# ioat91sam7x256 register map
Registers are 32-bit, access not given, no defined reset value unless marked. A register's access mark holds for its fields unless they carry their own. Addresses are absolute; registers are grouped by the start of their names; [hi:lo] are bit positions; {n}, {i} and the like mark numbered series; 'fields as' and 'values as' point back to an identical list.

## UDP
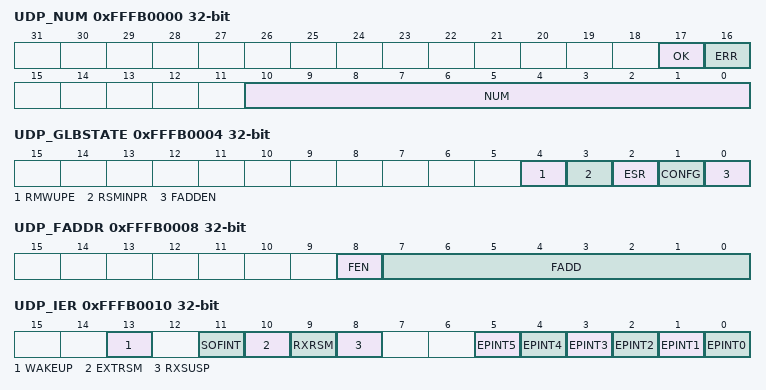
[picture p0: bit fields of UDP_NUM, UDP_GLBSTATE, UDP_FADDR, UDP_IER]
0xFFFB0000 UDP_NUM
  [17] OK, [16] ERR, [10:0] NUM
0xFFFB0004 UDP_GLBSTATE
  [4] RMWUPE, [3] RSMINPR, [2] ESR, [1] CONFG, [0] FADDEN
0xFFFB0008 UDP_FADDR
  [8] FEN, [7:0] FADD
0xFFFB0010 UDP_IER
  [13] WAKEUP, [11] SOFINT, [10] EXTRSM, [9] RXRSM, [8] RXSUSP, [n] EPINT{n} (n=0..5)
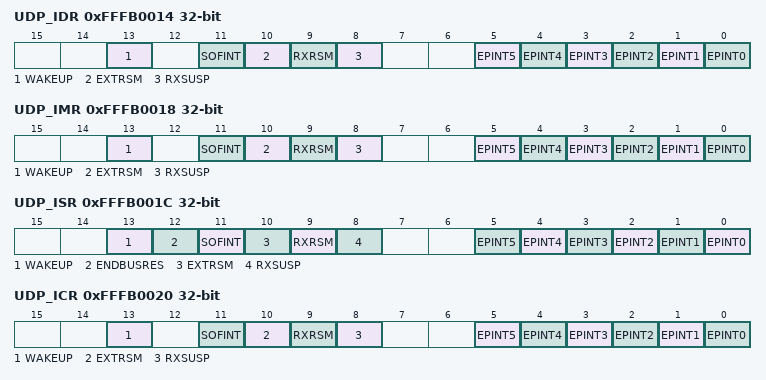
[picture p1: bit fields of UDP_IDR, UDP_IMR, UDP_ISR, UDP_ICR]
0xFFFB0014 UDP_IDR
  fields as UDP_IER
0xFFFB0018 UDP_IMR
  fields as UDP_IER
0xFFFB001C UDP_ISR
  [13] WAKEUP, [12] ENDBUSRES, [11] SOFINT, [10] EXTRSM, [9] RXRSM, [8] RXSUSP, [n] EPINT{n} (n=0..5)
0xFFFB0020 UDP_ICR
  fields as UDP_IER
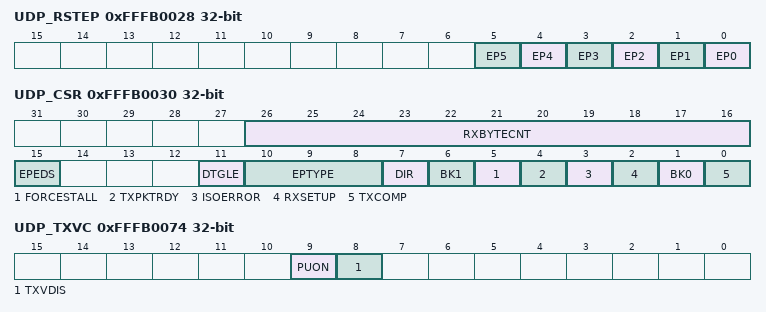
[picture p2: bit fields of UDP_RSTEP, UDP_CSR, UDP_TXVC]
0xFFFB0028 UDP_RSTEP
  [n] EP{n} (n=0..5)
0xFFFB0030 UDP_CSR
  [26:16] RXBYTECNT, [15] EPEDS, [11] DTGLE, [10:8] EPTYPE, [7] DIR, [6] BK1, [5] FORCESTALL, [4] TXPKTRDY, [3] ISOERROR, [2] RXSETUP, [1] BK0, [0] TXCOMP
0xFFFB0050 UDP_FDR
0xFFFB0074 UDP_TXVC
  [9] PUON, [8] TXVDIS

## TC0
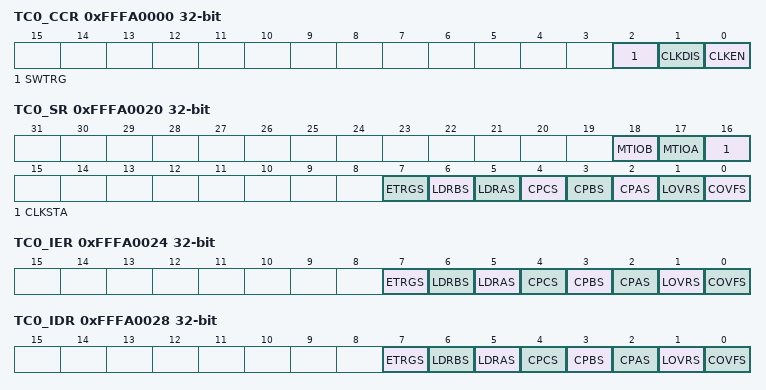
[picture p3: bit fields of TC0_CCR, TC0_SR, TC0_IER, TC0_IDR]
0xFFFA0000 TC0_CCR
  [2] SWTRG, [1] CLKDIS, [0] CLKEN
0xFFFA0004 TC0_CMR
  [31:30] BSWTRG, [29:28] BEEVT, [27:26] BCPC, [25:24] BCPB, [23:22] ASWTRG, [21:20] AEEVT, [19:18] ACPC, [19:18] LDRB, [17:16] ACPA, [17:16] LDRA, [15] WAVE, [14] CPCTRG, [14:13] WAVESEL, [12] ENETRG, [11:10] EEVT, [10] ABETRG, [9:8] ETRGEDG, [9:8] EEVTEDG, [7] CPCDIS, [7] LDBDIS, [6] CPCSTOP, [6] LDBSTOP, [5:4] BURST, [3] CLKI, [2:0] CLKS
0xFFFA0010 TC0_CV
0xFFFA0014 TC0_RA
0xFFFA0018 TC0_RB
0xFFFA001C TC0_RC
0xFFFA0020 TC0_SR
  [18] MTIOB, [17] MTIOA, [16] CLKSTA, [7] ETRGS, [6] LDRBS, [5] LDRAS, [4] CPCS, [3] CPBS, [2] CPAS, [1] LOVRS, [0] COVFS
0xFFFA0024 TC0_IER
  [7] ETRGS, [6] LDRBS, [5] LDRAS, [4] CPCS, [3] CPBS, [2] CPAS, [1] LOVRS, [0] COVFS
0xFFFA0028 TC0_IDR
  fields as TC0_IER
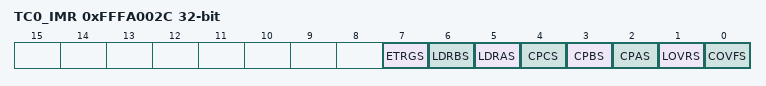
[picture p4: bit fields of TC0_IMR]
0xFFFA002C TC0_IMR
  fields as TC0_IER

## TC1
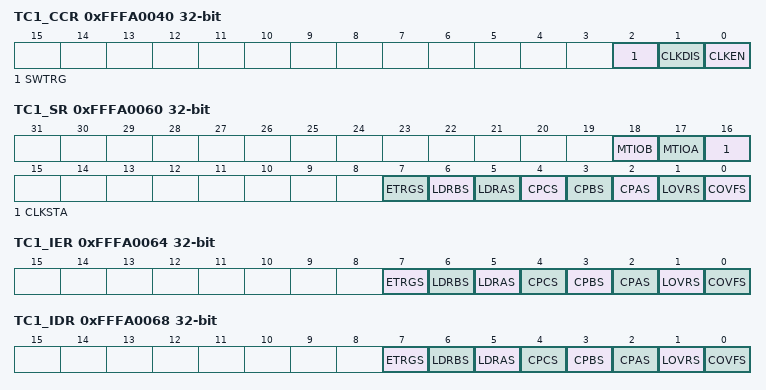
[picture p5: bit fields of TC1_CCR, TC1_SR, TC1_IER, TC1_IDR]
0xFFFA0040 TC1_CCR
  [2] SWTRG, [1] CLKDIS, [0] CLKEN
0xFFFA0044 TC1_CMR
  [31:30] BSWTRG, [29:28] BEEVT, [27:26] BCPC, [25:24] BCPB, [23:22] ASWTRG, [21:20] AEEVT, [19:18] ACPC, [19:18] LDRB, [17:16] ACPA, [17:16] LDRA, [15] WAVE, [14] CPCTRG, [14:13] WAVESEL, [12] ENETRG, [11:10] EEVT, [10] ABETRG, [9:8] ETRGEDG, [9:8] EEVTEDG, [7] CPCDIS, [7] LDBDIS, [6] CPCSTOP, [6] LDBSTOP, [5:4] BURST, [3] CLKI, [2:0] CLKS
0xFFFA0050 TC1_CV
0xFFFA0054 TC1_RA
0xFFFA0058 TC1_RB
0xFFFA005C TC1_RC
0xFFFA0060 TC1_SR
  [18] MTIOB, [17] MTIOA, [16] CLKSTA, [7] ETRGS, [6] LDRBS, [5] LDRAS, [4] CPCS, [3] CPBS, [2] CPAS, [1] LOVRS, [0] COVFS
0xFFFA0064 TC1_IER
  [7] ETRGS, [6] LDRBS, [5] LDRAS, [4] CPCS, [3] CPBS, [2] CPAS, [1] LOVRS, [0] COVFS
0xFFFA0068 TC1_IDR
  fields as TC1_IER
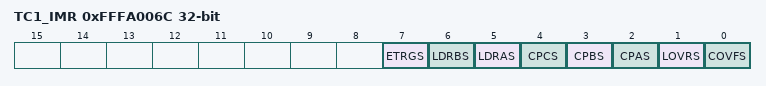
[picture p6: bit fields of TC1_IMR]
0xFFFA006C TC1_IMR
  fields as TC1_IER

## TC2
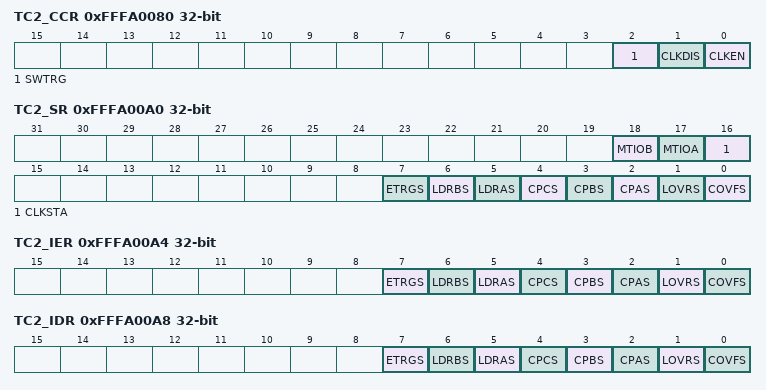
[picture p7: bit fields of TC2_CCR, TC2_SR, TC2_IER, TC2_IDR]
0xFFFA0080 TC2_CCR
  [2] SWTRG, [1] CLKDIS, [0] CLKEN
0xFFFA0084 TC2_CMR
  [31:30] BSWTRG, [29:28] BEEVT, [27:26] BCPC, [25:24] BCPB, [23:22] ASWTRG, [21:20] AEEVT, [19:18] ACPC, [19:18] LDRB, [17:16] ACPA, [17:16] LDRA, [15] WAVE, [14] CPCTRG, [14:13] WAVESEL, [12] ENETRG, [11:10] EEVT, [10] ABETRG, [9:8] ETRGEDG, [9:8] EEVTEDG, [7] CPCDIS, [7] LDBDIS, [6] CPCSTOP, [6] LDBSTOP, [5:4] BURST, [3] CLKI, [2:0] CLKS
0xFFFA0090 TC2_CV
0xFFFA0094 TC2_RA
0xFFFA0098 TC2_RB
0xFFFA009C TC2_RC
0xFFFA00A0 TC2_SR
  [18] MTIOB, [17] MTIOA, [16] CLKSTA, [7] ETRGS, [6] LDRBS, [5] LDRAS, [4] CPCS, [3] CPBS, [2] CPAS, [1] LOVRS, [0] COVFS
0xFFFA00A4 TC2_IER
  [7] ETRGS, [6] LDRBS, [5] LDRAS, [4] CPCS, [3] CPBS, [2] CPAS, [1] LOVRS, [0] COVFS
0xFFFA00A8 TC2_IDR
  fields as TC2_IER
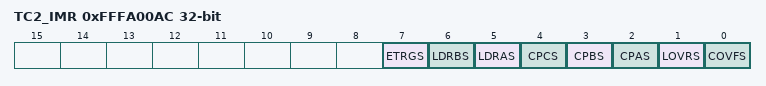
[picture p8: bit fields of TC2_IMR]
0xFFFA00AC TC2_IMR
  fields as TC2_IER

## TCB
0xFFFA00C0 TCB_BCR
  [0] SYNC
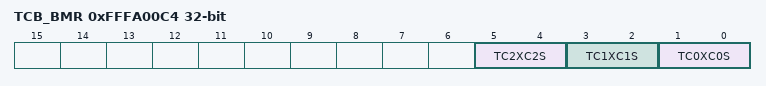
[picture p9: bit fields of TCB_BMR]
0xFFFA00C4 TCB_BMR
  [5:4] TC2XC2S, [3:2] TC1XC1S, [1:0] TC0XC0S

## CAN
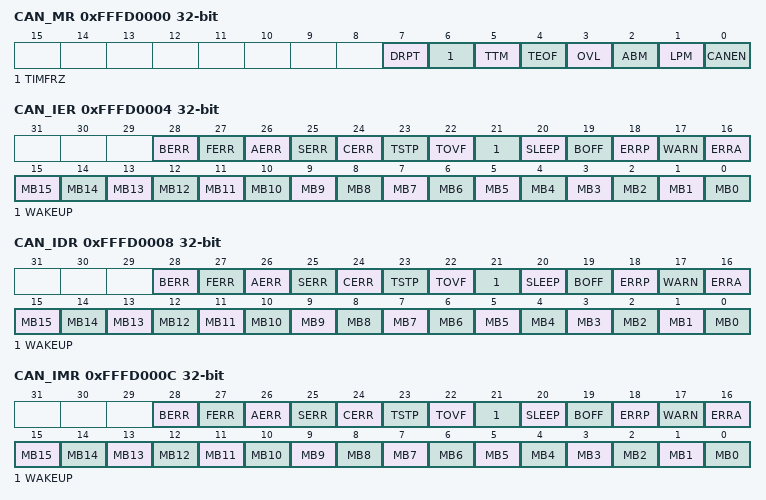
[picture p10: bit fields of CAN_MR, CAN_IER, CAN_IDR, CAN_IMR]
0xFFFD0000 CAN_MR
  [7] DRPT, [6] TIMFRZ, [5] TTM, [4] TEOF, [3] OVL, [2] ABM, [1] LPM, [0] CANEN
0xFFFD0004 CAN_IER
  [28] BERR, [27] FERR, [26] AERR, [25] SERR, [24] CERR, [23] TSTP, [22] TOVF, [21] WAKEUP, [20] SLEEP, [19] BOFF, [18] ERRP, [17] WARN, [16] ERRA, [n] MB{n} (n=0..15)
0xFFFD0008 CAN_IDR
  fields as CAN_IER
0xFFFD000C CAN_IMR
  fields as CAN_IER
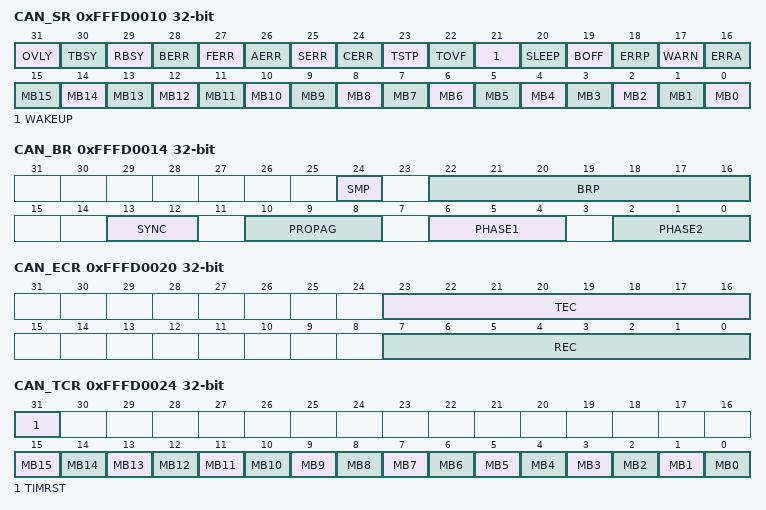
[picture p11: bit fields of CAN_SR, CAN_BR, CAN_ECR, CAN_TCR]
0xFFFD0010 CAN_SR
  [31] OVLY, [30] TBSY, [29] RBSY, [28] BERR, [27] FERR, [26] AERR, [25] SERR, [24] CERR, [23] TSTP, [22] TOVF, [21] WAKEUP, [20] SLEEP, [19] BOFF, [18] ERRP, [17] WARN, [16] ERRA, [n] MB{n} (n=0..15)
0xFFFD0014 CAN_BR
  [24] SMP, [22:16] BRP, [13:12] SYNC, [10:8] PROPAG, [6:4] PHASE1, [2:0] PHASE2
0xFFFD0018 CAN_TIM
  [15:0] TIMER
0xFFFD001C CAN_TIMESTP
  [15:0] MTIMESTAMP
0xFFFD0020 CAN_ECR
  [23:16] TEC, [7:0] REC
0xFFFD0024 CAN_TCR
  [31] TIMRST, [n] MB{n} (n=0..15)
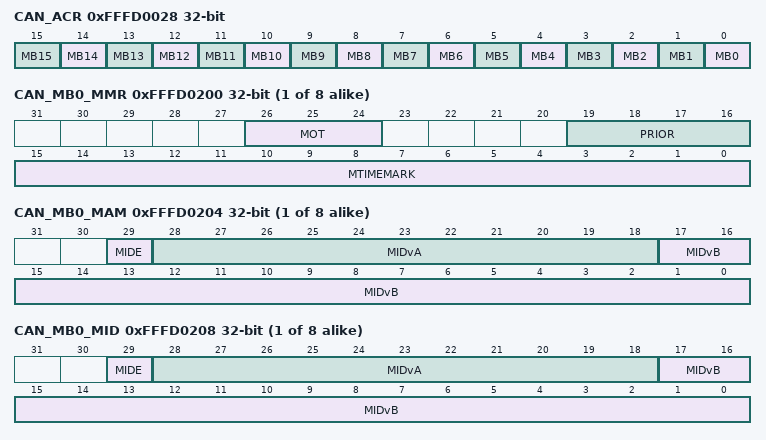
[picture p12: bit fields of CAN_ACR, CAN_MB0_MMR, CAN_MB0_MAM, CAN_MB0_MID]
0xFFFD0028 CAN_ACR
  [n] MB{n} (n=0..15)
0xFFFD00FC CAN_VR
{0xFFFD0200+0x20*i} CAN_MB{i}_MMR (i=0..7)
  [26:24] MOT, [19:16] PRIOR, [15:0] MTIMEMARK
{0xFFFD0204+0x20*i} CAN_MB{i}_MAM (i=0..7)
  [29] MIDE, [28:18] MIDvA, [17:0] MIDvB
{0xFFFD0208+0x20*i} CAN_MB{i}_MID (i=0..7)
  [29] MIDE, [28:18] MIDvA, [17:0] MIDvB
{0xFFFD020C+0x20*i} CAN_MB{i}_MFID (i=0..7)
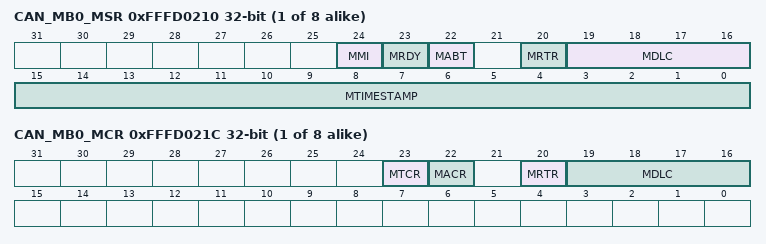
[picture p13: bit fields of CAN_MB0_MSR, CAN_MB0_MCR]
{0xFFFD0210+0x20*i} CAN_MB{i}_MSR (i=0..7)
  [24] MMI, [23] MRDY, [22] MABT, [20] MRTR, [19:16] MDLC, [15:0] MTIMESTAMP
{0xFFFD0214+0x20*i} CAN_MB{i}_MDL (i=0..7)
{0xFFFD0218+0x20*i} CAN_MB{i}_MDH (i=0..7)
{0xFFFD021C+0x20*i} CAN_MB{i}_MCR (i=0..7)
  [23] MTCR, [22] MACR, [20] MRTR, [19:16] MDLC

## EMAC
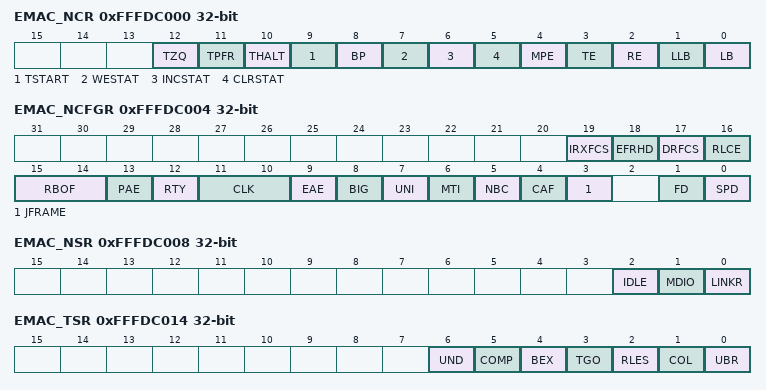
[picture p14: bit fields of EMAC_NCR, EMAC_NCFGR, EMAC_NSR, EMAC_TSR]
0xFFFDC000 EMAC_NCR
  [12] TZQ, [11] TPFR, [10] THALT, [9] TSTART, [8] BP, [7] WESTAT, [6] INCSTAT, [5] CLRSTAT, [4] MPE, [3] TE, [2] RE, [1] LLB, [0] LB
0xFFFDC004 EMAC_NCFGR
  [19] IRXFCS, [18] EFRHD, [17] DRFCS, [16] RLCE, [15:14] RBOF, [13] PAE, [12] RTY, [11:10] CLK, [9] EAE, [8] BIG, [7] UNI, [6] MTI, [5] NBC, [4] CAF, [3] JFRAME, [1] FD, [0] SPD
0xFFFDC008 EMAC_NSR
  [2] IDLE, [1] MDIO, [0] LINKR
0xFFFDC014 EMAC_TSR
  [6] UND, [5] COMP, [4] BEX, [3] TGO, [2] RLES, [1] COL, [0] UBR
0xFFFDC018 EMAC_RBQP
0xFFFDC01C EMAC_TBQP
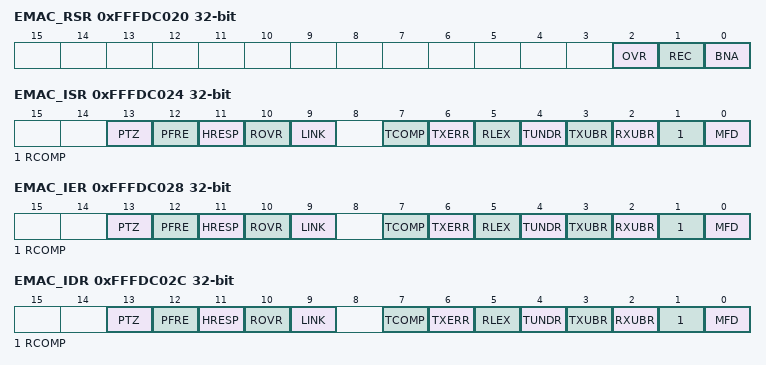
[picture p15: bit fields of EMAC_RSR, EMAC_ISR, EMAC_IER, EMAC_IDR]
0xFFFDC020 EMAC_RSR
  [2] OVR, [1] REC, [0] BNA
0xFFFDC024 EMAC_ISR
  [13] PTZ, [12] PFRE, [11] HRESP, [10] ROVR, [9] LINK, [7] TCOMP, [6] TXERR, [5] RLEX, [4] TUNDR, [3] TXUBR, [2] RXUBR, [1] RCOMP, [0] MFD
0xFFFDC028 EMAC_IER
  fields as EMAC_ISR
0xFFFDC02C EMAC_IDR
  fields as EMAC_ISR
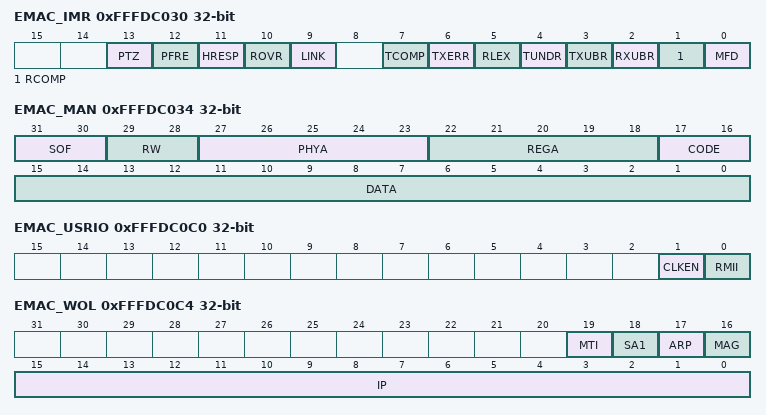
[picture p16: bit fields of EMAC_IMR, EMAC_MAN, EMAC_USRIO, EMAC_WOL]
0xFFFDC030 EMAC_IMR
  fields as EMAC_ISR
0xFFFDC034 EMAC_MAN
  [31:30] SOF, [29:28] RW, [27:23] PHYA, [22:18] REGA, [17:16] CODE, [15:0] DATA
0xFFFDC038 EMAC_PTR
0xFFFDC03C EMAC_PFR
0xFFFDC040 EMAC_FTO
0xFFFDC044 EMAC_SCF
0xFFFDC048 EMAC_MCF
0xFFFDC04C EMAC_FRO
0xFFFDC050 EMAC_FCSE
0xFFFDC054 EMAC_ALE
0xFFFDC058 EMAC_DTF
0xFFFDC05C EMAC_LCOL
0xFFFDC060 EMAC_ECOL
0xFFFDC064 EMAC_TUND
0xFFFDC068 EMAC_CSE
0xFFFDC06C EMAC_RRE
0xFFFDC070 EMAC_ROV
0xFFFDC074 EMAC_RSE
0xFFFDC078 EMAC_ELE
0xFFFDC07C EMAC_RJA
0xFFFDC080 EMAC_USF
0xFFFDC084 EMAC_STE
0xFFFDC088 EMAC_RLE
0xFFFDC08C EMAC_TPF
0xFFFDC090 EMAC_HRB
0xFFFDC094 EMAC_HRT
{0xFFFDC090+8i} EMAC_SA{i}L (i=1..4)
{0xFFFDC094+8i} EMAC_SA{i}H (i=1..4)
0xFFFDC0B8 EMAC_TID
0xFFFDC0BC EMAC_TPQ
0xFFFDC0C0 EMAC_USRIO
  [1] CLKEN, [0] RMII
0xFFFDC0C4 EMAC_WOL
  [19] MTI, [18] SA1, [17] ARP, [16] MAG, [15:0] IP
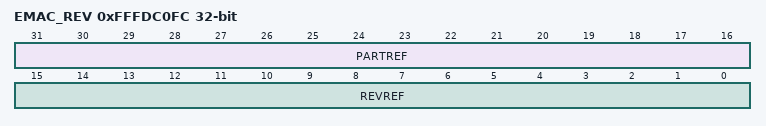
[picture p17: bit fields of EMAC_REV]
0xFFFDC0FC EMAC_REV
  [31:16] PARTREF, [15:0] REVREF

## ADC
0xFFFD8000 ADC_CR
  [1] START, [0] SWRST
0xFFFD8004 ADC_MR
  [27:24] SHTIM, [20:16] STARTUP, [13:8] PRESCAL, [5] SLEEP, [4] LOWRES, [3:1] TRGSEL, [0] TRGEN
0xFFFD8010 ADC_CHER
  [n] CH{n} (n=0..7)
0xFFFD8014 ADC_CHDR
  [n] CH{n} (n=0..7)
0xFFFD8018 ADC_CHSR
  [n] CH{n} (n=0..7)
0xFFFD801C ADC_SR
  [19] RXBUFF, [18] ENDRX, [17] GOVRE, [16] DRDY, [n+8] OVRE{n} (n=0..7), [n] EOC{n} (n=0..7)
0xFFFD8020 ADC_LCDR
  [9:0] LDATA
0xFFFD8024 ADC_IER
  fields as ADC_SR
0xFFFD8028 ADC_IDR
  fields as ADC_SR
0xFFFD802C ADC_IMR
  fields as ADC_SR
{0xFFFD8030+4i} ADC_CDR{i} (i=0..7)
  [9:0] DATA
0xFFFD8100 ADC_RPR
0xFFFD8104 ADC_RCR
0xFFFD8108 ADC_TPR
0xFFFD810C ADC_TCR
0xFFFD8110 ADC_RNPR
0xFFFD8114 ADC_RNCR
0xFFFD8118 ADC_TNPR
0xFFFD811C ADC_TNCR
0xFFFD8120 ADC_PTCR
  [9] TXTDIS, [8] TXTEN, [1] RXTDIS, [0] RXTEN
0xFFFD8124 ADC_PTSR
  [8] TXTEN, [0] RXTEN

## SFR
0xFFFFFD60 VREG_MR
  [0] PSTDBY
